AUTOSAR XML (schema 00053)
package /MICROSAR/NvM_swc/DataTypes
  impl type NvM_BlockIdType: range raw 1..32767, implementation-data-type=uint16
package /MICROSAR/NvM_swc/Interfaces
  client server interface NvMAdministration: is-service=true, service-kind=NON-VOLATILE-RAM-MANAGER
    operation SetBlockProtection: possible-error=NvMAdministration/E_NOT_OK
      arg ProtectionEnabled: type=boolean, direction=IN
    error E_NOT_OK: error-code=1
  client server interface NvMService_AC3_SRBS: is-service=true, service-kind=NON-VOLATILE-RAM-MANAGER
    7 x operation, all with possible-error=NvMService_AC3_SRBS/E_NOT_OK:
      GetErrorStatus
        arg ErrorStatus: type=NvM_RequestResultType, direction=OUT
      SetRamBlockStatus
        arg RamBlockStatus: type=boolean, direction=IN
      ReadBlock
        arg DstPtr: type=dtRef_VOID, direction=IN
      WriteBlock
        arg SrcPtr: type=dtRef_const_VOID, direction=IN
      RestoreBlockDefaults
        arg DstPtr: type=dtRef_VOID, direction=IN
      InvalidateNvBlock
      EraseBlock
    error E_NOT_OK: error-code=1
  client server interface NvMService_AC3_SRBS_Defs: is-service=true, service-kind=NON-VOLATILE-RAM-MANAGER
    7 x operation, all with possible-error=NvMService_AC3_SRBS_Defs/E_NOT_OK:
      GetErrorStatus
        arg ErrorStatus: type=NvM_RequestResultType, direction=OUT
      SetRamBlockStatus
        arg RamBlockStatus: type=boolean, direction=IN
      ReadBlock
        arg DstPtr: type=dtRef_VOID, direction=IN
      WriteBlock
        arg SrcPtr: type=dtRef_const_VOID, direction=IN
      RestoreBlockDefaults
        arg DstPtr: type=dtRef_VOID, direction=IN
      InvalidateNvBlock
      EraseBlock
    error E_NOT_OK: error-code=1
package /MICROSAR/NvM_swc/ComponentTypes
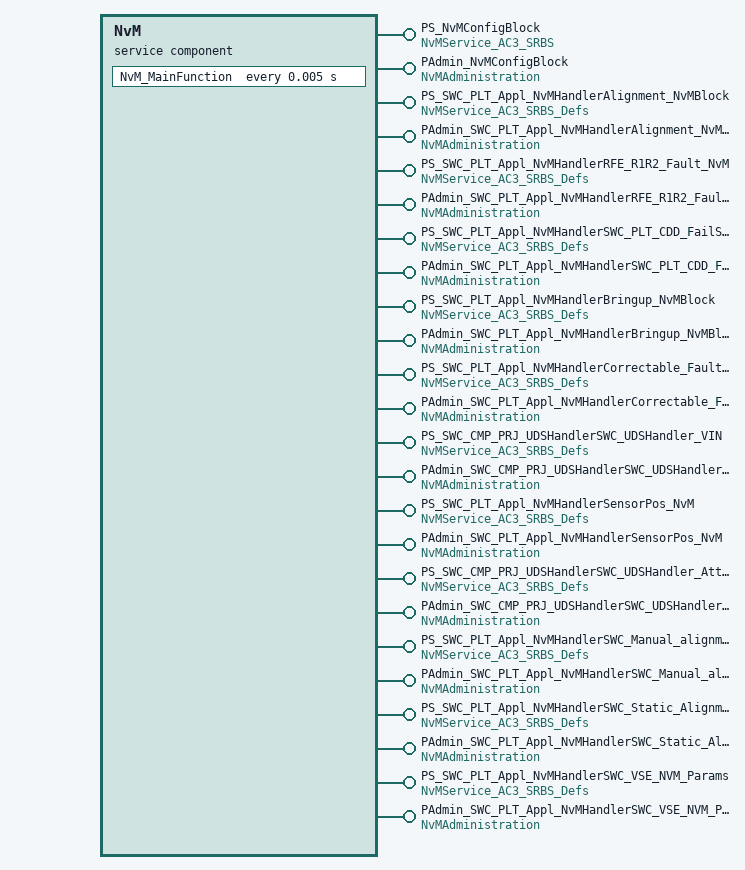
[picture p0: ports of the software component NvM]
  service sw component type NvM: category=SERVICE_COMPONENT
    24 x provide port:
      PS_NvMConfigBlock: provided-interface=NvMService_AC3_SRBS
      PAdmin_NvMConfigBlock: provided-interface=NvMAdministration
      PS_SWC_PLT_Appl_NvMHandlerAlignment_NvMBlock: provided-interface=NvMService_AC3_SRBS_Defs
      PAdmin_SWC_PLT_Appl_NvMHandlerAlignment_NvMBlock: provided-interface=NvMAdministration
      PS_SWC_PLT_Appl_NvMHandlerRFE_R1R2_Fault_NvM: provided-interface=NvMService_AC3_SRBS_Defs
      PAdmin_SWC_PLT_Appl_NvMHandlerRFE_R1R2_Fault_NvM: provided-interface=NvMAdministration
      PS_SWC_PLT_Appl_NvMHandlerSWC_PLT_CDD_FailSafe: provided-interface=NvMService_AC3_SRBS_Defs
      PAdmin_SWC_PLT_Appl_NvMHandlerSWC_PLT_CDD_FailSafe: provided-interface=NvMAdministration
      PS_SWC_PLT_Appl_NvMHandlerBringup_NvMBlock: provided-interface=NvMService_AC3_SRBS_Defs
      PAdmin_SWC_PLT_Appl_NvMHandlerBringup_NvMBlock: provided-interface=NvMAdministration
      PS_SWC_PLT_Appl_NvMHandlerCorrectable_Fault_NvM: provided-interface=NvMService_AC3_SRBS_Defs
      PAdmin_SWC_PLT_Appl_NvMHandlerCorrectable_Fault_NvM: provided-interface=NvMAdministration
      PS_SWC_CMP_PRJ_UDSHandlerSWC_UDSHandler_VIN: provided-interface=NvMService_AC3_SRBS_Defs
      PAdmin_SWC_CMP_PRJ_UDSHandlerSWC_UDSHandler_VIN: provided-interface=NvMAdministration
      PS_SWC_PLT_Appl_NvMHandlerSensorPos_NvM: provided-interface=NvMService_AC3_SRBS_Defs
      PAdmin_SWC_PLT_Appl_NvMHandlerSensorPos_NvM: provided-interface=NvMAdministration
      PS_SWC_CMP_PRJ_UDSHandlerSWC_UDSHandler_Attemptcounter: provided-interface=NvMService_AC3_SRBS_Defs
      PAdmin_SWC_CMP_PRJ_UDSHandlerSWC_UDSHandler_Attemptcounter: provided-interface=NvMAdministration
      PS_SWC_PLT_Appl_NvMHandlerSWC_Manual_alignment_Execution: provided-interface=NvMService_AC3_SRBS_Defs
      PAdmin_SWC_PLT_Appl_NvMHandlerSWC_Manual_alignment_Execution: provided-interface=NvMAdministration
      PS_SWC_PLT_Appl_NvMHandlerSWC_Static_Alignment_Write_Parameters: provided-interface=NvMService_AC3_SRBS_Defs
      PAdmin_SWC_PLT_Appl_NvMHandlerSWC_Static_Alignment_Write_Parameters: provided-interface=NvMAdministration
      PS_SWC_PLT_Appl_NvMHandlerSWC_VSE_NVM_Params: provided-interface=NvMService_AC3_SRBS_Defs
      PAdmin_SWC_PLT_Appl_NvMHandlerSWC_VSE_NVM_Params: provided-interface=NvMAdministration
    behavior NvMInternalBehavior: handle-termination-and-restart=NO-SUPPORT
      timing event Timer_NvM_MainFunction: start-on-event=NvM_MainFunction, period=0.005
      96 x operation invoked event:
        OpEventGetErrorStatus_GetErrorStatus_PS_NvMConfigBlock: start-on-event=GetErrorStatus, operation=PS_NvMConfigBlock.GetErrorStatus
        OpEventSetRamBlockStatus_SetRamBlockStatus_PS_NvMConfigBlock: start-on-event=SetRamBlockStatus, operation=PS_NvMConfigBlock.SetRamBlockStatus
        OpEventReadBlock_ReadBlock_PS_NvMConfigBlock: start-on-event=ReadBlock, operation=PS_NvMConfigBlock.ReadBlock
        OpEventWriteBlock_WriteBlock_PS_NvMConfigBlock: start-on-event=WriteBlock, operation=PS_NvMConfigBlock.WriteBlock
        OpEventRestoreBlockDefaults_RestoreBlockDefaults_PS_NvMConfigBlock: start-on-event=RestoreBlockDefaults, operation=PS_NvMConfigBlock.RestoreBlockDefaults
        OpEventInvalidateNvBlock_InvalidateNvBlock_PS_NvMConfigBlock: start-on-event=InvalidateNvBlock, operation=PS_NvMConfigBlock.InvalidateNvBlock
        OpEventEraseBlock_EraseBlock_PS_NvMConfigBlock: start-on-event=EraseBlock, operation=PS_NvMConfigBlock.EraseBlock
        OpEventSetBlockProtection_SetBlockProtection_PAdmin_NvMConfigBlock: start-on-event=SetBlockProtection, operation=PAdmin_NvMConfigBlock.SetBlockProtection
        OpEventGetErrorStatus_GetErrorStatus_PS_SWC_PLT_Appl_NvMHandlerAlignment_NvMBlock: start-on-event=GetErrorStatus, operation=PS_SWC_PLT_Appl_NvMHandlerAlignment_NvMBlock.GetErrorStatus
        OpEventGetErrorStatus_GetErrorStatus_PS_SWC_PLT_Appl_NvMHandlerRFE_R1R2_Fault_NvM: start-on-event=GetErrorStatus, operation=PS_SWC_PLT_Appl_NvMHandlerRFE_R1R2_Fault_NvM.GetErrorStatus
        OpEventGetErrorStatus_GetErrorStatus_PS_SWC_PLT_Appl_NvMHandlerSWC_PLT_CDD_FailSafe: start-on-event=GetErrorStatus, operation=PS_SWC_PLT_Appl_NvMHandlerSWC_PLT_CDD_FailSafe.GetErrorStatus
        OpEventSetRamBlockStatus_SetRamBlockStatus_PS_SWC_PLT_Appl_NvMHandlerAlignment_NvMBlock: start-on-event=SetRamBlockStatus, operation=PS_SWC_PLT_Appl_NvMHandlerAlignment_NvMBlock.SetRamBlockStatus
        OpEventSetRamBlockStatus_SetRamBlockStatus_PS_SWC_PLT_Appl_NvMHandlerRFE_R1R2_Fault_NvM: start-on-event=SetRamBlockStatus, operation=PS_SWC_PLT_Appl_NvMHandlerRFE_R1R2_Fault_NvM.SetRamBlockStatus
        OpEventSetRamBlockStatus_SetRamBlockStatus_PS_SWC_PLT_Appl_NvMHandlerSWC_PLT_CDD_FailSafe: start-on-event=SetRamBlockStatus, operation=PS_SWC_PLT_Appl_NvMHandlerSWC_PLT_CDD_FailSafe.SetRamBlockStatus
        OpEventReadBlock_ReadBlock_PS_SWC_PLT_Appl_NvMHandlerAlignment_NvMBlock: start-on-event=ReadBlock, operation=PS_SWC_PLT_Appl_NvMHandlerAlignment_NvMBlock.ReadBlock
        OpEventReadBlock_ReadBlock_PS_SWC_PLT_Appl_NvMHandlerRFE_R1R2_Fault_NvM: start-on-event=ReadBlock, operation=PS_SWC_PLT_Appl_NvMHandlerRFE_R1R2_Fault_NvM.ReadBlock
        OpEventReadBlock_ReadBlock_PS_SWC_PLT_Appl_NvMHandlerSWC_PLT_CDD_FailSafe: start-on-event=ReadBlock, operation=PS_SWC_PLT_Appl_NvMHandlerSWC_PLT_CDD_FailSafe.ReadBlock
        OpEventWriteBlock_WriteBlock_PS_SWC_PLT_Appl_NvMHandlerAlignment_NvMBlock: start-on-event=WriteBlock, operation=PS_SWC_PLT_Appl_NvMHandlerAlignment_NvMBlock.WriteBlock
        OpEventWriteBlock_WriteBlock_PS_SWC_PLT_Appl_NvMHandlerRFE_R1R2_Fault_NvM: start-on-event=WriteBlock, operation=PS_SWC_PLT_Appl_NvMHandlerRFE_R1R2_Fault_NvM.WriteBlock
        OpEventWriteBlock_WriteBlock_PS_SWC_PLT_Appl_NvMHandlerSWC_PLT_CDD_FailSafe: start-on-event=WriteBlock, operation=PS_SWC_PLT_Appl_NvMHandlerSWC_PLT_CDD_FailSafe.WriteBlock
        OpEventRestoreBlockDefaults_RestoreBlockDefaults_PS_SWC_PLT_Appl_NvMHandlerAlignment_NvMBlock: start-on-event=RestoreBlockDefaults, operation=PS_SWC_PLT_Appl_NvMHandlerAlignment_NvMBlock.RestoreBlockDefaults
        OpEventRestoreBlockDefaults_RestoreBlockDefaults_PS_SWC_PLT_Appl_NvMHandlerRFE_R1R2_Fault_NvM: start-on-event=RestoreBlockDefaults, operation=PS_SWC_PLT_Appl_NvMHandlerRFE_R1R2_Fault_NvM.RestoreBlockDefaults
        OpEventRestoreBlockDefaults_RestoreBlockDefaults_PS_SWC_PLT_Appl_NvMHandlerSWC_PLT_CDD_FailSafe: start-on-event=RestoreBlockDefaults, operation=PS_SWC_PLT_Appl_NvMHandlerSWC_PLT_CDD_FailSafe.RestoreBlockDefaults
        OpEventInvalidateNvBlock_InvalidateNvBlock_PS_SWC_PLT_Appl_NvMHandlerAlignment_NvMBlock: start-on-event=InvalidateNvBlock, operation=PS_SWC_PLT_Appl_NvMHandlerAlignment_NvMBlock.InvalidateNvBlock
        OpEventInvalidateNvBlock_InvalidateNvBlock_PS_SWC_PLT_Appl_NvMHandlerRFE_R1R2_Fault_NvM: start-on-event=InvalidateNvBlock, operation=PS_SWC_PLT_Appl_NvMHandlerRFE_R1R2_Fault_NvM.InvalidateNvBlock
        OpEventInvalidateNvBlock_InvalidateNvBlock_PS_SWC_PLT_Appl_NvMHandlerSWC_PLT_CDD_FailSafe: start-on-event=InvalidateNvBlock, operation=PS_SWC_PLT_Appl_NvMHandlerSWC_PLT_CDD_FailSafe.InvalidateNvBlock
        OpEventEraseBlock_EraseBlock_PS_SWC_PLT_Appl_NvMHandlerAlignment_NvMBlock: start-on-event=EraseBlock, operation=PS_SWC_PLT_Appl_NvMHandlerAlignment_NvMBlock.EraseBlock
        OpEventEraseBlock_EraseBlock_PS_SWC_PLT_Appl_NvMHandlerRFE_R1R2_Fault_NvM: start-on-event=EraseBlock, operation=PS_SWC_PLT_Appl_NvMHandlerRFE_R1R2_Fault_NvM.EraseBlock
        OpEventEraseBlock_EraseBlock_PS_SWC_PLT_Appl_NvMHandlerSWC_PLT_CDD_FailSafe: start-on-event=EraseBlock, operation=PS_SWC_PLT_Appl_NvMHandlerSWC_PLT_CDD_FailSafe.EraseBlock
        OpEventSetBlockProtection_SetBlockProtection_PAdmin_SWC_PLT_Appl_NvMHandlerAlignment_NvMBlock: start-on-event=SetBlockProtection, operation=PAdmin_SWC_PLT_Appl_NvMHandlerAlignment_NvMBlock.SetBlockProtection
        OpEventSetBlockProtection_SetBlockProtection_PAdmin_SWC_PLT_Appl_NvMHandlerRFE_R1R2_Fault_NvM: start-on-event=SetBlockProtection, operation=PAdmin_SWC_PLT_Appl_NvMHandlerRFE_R1R2_Fault_NvM.SetBlockProtection
        OpEventSetBlockProtection_SetBlockProtection_PAdmin_SWC_PLT_Appl_NvMHandlerSWC_PLT_CDD_FailSafe: start-on-event=SetBlockProtection, operation=PAdmin_SWC_PLT_Appl_NvMHandlerSWC_PLT_CDD_FailSafe.SetBlockProtection
        OpEventGetErrorStatus_GetErrorStatus_PS_SWC_PLT_Appl_NvMHandlerBringup_NvMBlock: start-on-event=GetErrorStatus, operation=PS_SWC_PLT_Appl_NvMHandlerBringup_NvMBlock.GetErrorStatus
        OpEventSetRamBlockStatus_SetRamBlockStatus_PS_SWC_PLT_Appl_NvMHandlerBringup_NvMBlock: start-on-event=SetRamBlockStatus, operation=PS_SWC_PLT_Appl_NvMHandlerBringup_NvMBlock.SetRamBlockStatus
        OpEventReadBlock_ReadBlock_PS_SWC_PLT_Appl_NvMHandlerBringup_NvMBlock: start-on-event=ReadBlock, operation=PS_SWC_PLT_Appl_NvMHandlerBringup_NvMBlock.ReadBlock
        OpEventWriteBlock_WriteBlock_PS_SWC_PLT_Appl_NvMHandlerBringup_NvMBlock: start-on-event=WriteBlock, operation=PS_SWC_PLT_Appl_NvMHandlerBringup_NvMBlock.WriteBlock
        OpEventRestoreBlockDefaults_RestoreBlockDefaults_PS_SWC_PLT_Appl_NvMHandlerBringup_NvMBlock: start-on-event=RestoreBlockDefaults, operation=PS_SWC_PLT_Appl_NvMHandlerBringup_NvMBlock.RestoreBlockDefaults
        OpEventInvalidateNvBlock_InvalidateNvBlock_PS_SWC_PLT_Appl_NvMHandlerBringup_NvMBlock: start-on-event=InvalidateNvBlock, operation=PS_SWC_PLT_Appl_NvMHandlerBringup_NvMBlock.InvalidateNvBlock
        OpEventEraseBlock_EraseBlock_PS_SWC_PLT_Appl_NvMHandlerBringup_NvMBlock: start-on-event=EraseBlock, operation=PS_SWC_PLT_Appl_NvMHandlerBringup_NvMBlock.EraseBlock
        OpEventSetBlockProtection_SetBlockProtection_PAdmin_SWC_PLT_Appl_NvMHandlerBringup_NvMBlock: start-on-event=SetBlockProtection, operation=PAdmin_SWC_PLT_Appl_NvMHandlerBringup_NvMBlock.SetBlockProtection
        OpEventGetErrorStatus_GetErrorStatus_PS_SWC_PLT_Appl_NvMHandlerCorrectable_Fault_NvM: start-on-event=GetErrorStatus, operation=PS_SWC_PLT_Appl_NvMHandlerCorrectable_Fault_NvM.GetErrorStatus
        OpEventSetRamBlockStatus_SetRamBlockStatus_PS_SWC_PLT_Appl_NvMHandlerCorrectable_Fault_NvM: start-on-event=SetRamBlockStatus, operation=PS_SWC_PLT_Appl_NvMHandlerCorrectable_Fault_NvM.SetRamBlockStatus
        OpEventReadBlock_ReadBlock_PS_SWC_PLT_Appl_NvMHandlerCorrectable_Fault_NvM: start-on-event=ReadBlock, operation=PS_SWC_PLT_Appl_NvMHandlerCorrectable_Fault_NvM.ReadBlock
        OpEventWriteBlock_WriteBlock_PS_SWC_PLT_Appl_NvMHandlerCorrectable_Fault_NvM: start-on-event=WriteBlock, operation=PS_SWC_PLT_Appl_NvMHandlerCorrectable_Fault_NvM.WriteBlock
        OpEventRestoreBlockDefaults_RestoreBlockDefaults_PS_SWC_PLT_Appl_NvMHandlerCorrectable_Fault_NvM: start-on-event=RestoreBlockDefaults, operation=PS_SWC_PLT_Appl_NvMHandlerCorrectable_Fault_NvM.RestoreBlockDefaults
        OpEventInvalidateNvBlock_InvalidateNvBlock_PS_SWC_PLT_Appl_NvMHandlerCorrectable_Fault_NvM: start-on-event=InvalidateNvBlock, operation=PS_SWC_PLT_Appl_NvMHandlerCorrectable_Fault_NvM.InvalidateNvBlock
        OpEventEraseBlock_EraseBlock_PS_SWC_PLT_Appl_NvMHandlerCorrectable_Fault_NvM: start-on-event=EraseBlock, operation=PS_SWC_PLT_Appl_NvMHandlerCorrectable_Fault_NvM.EraseBlock
        OpEventSetBlockProtection_SetBlockProtection_PAdmin_SWC_PLT_Appl_NvMHandlerCorrectable_Fault_NvM: start-on-event=SetBlockProtection, operation=PAdmin_SWC_PLT_Appl_NvMHandlerCorrectable_Fault_NvM.SetBlockProtection
        OpEventGetErrorStatus_GetErrorStatus_PS_SWC_CMP_PRJ_UDSHandlerSWC_UDSHandler_VIN: start-on-event=GetErrorStatus, operation=PS_SWC_CMP_PRJ_UDSHandlerSWC_UDSHandler_VIN.GetErrorStatus
        OpEventSetRamBlockStatus_SetRamBlockStatus_PS_SWC_CMP_PRJ_UDSHandlerSWC_UDSHandler_VIN: start-on-event=SetRamBlockStatus, operation=PS_SWC_CMP_PRJ_UDSHandlerSWC_UDSHandler_VIN.SetRamBlockStatus
        OpEventReadBlock_ReadBlock_PS_SWC_CMP_PRJ_UDSHandlerSWC_UDSHandler_VIN: start-on-event=ReadBlock, operation=PS_SWC_CMP_PRJ_UDSHandlerSWC_UDSHandler_VIN.ReadBlock
        OpEventWriteBlock_WriteBlock_PS_SWC_CMP_PRJ_UDSHandlerSWC_UDSHandler_VIN: start-on-event=WriteBlock, operation=PS_SWC_CMP_PRJ_UDSHandlerSWC_UDSHandler_VIN.WriteBlock
        OpEventRestoreBlockDefaults_RestoreBlockDefaults_PS_SWC_CMP_PRJ_UDSHandlerSWC_UDSHandler_VIN: start-on-event=RestoreBlockDefaults, operation=PS_SWC_CMP_PRJ_UDSHandlerSWC_UDSHandler_VIN.RestoreBlockDefaults
        OpEventInvalidateNvBlock_InvalidateNvBlock_PS_SWC_CMP_PRJ_UDSHandlerSWC_UDSHandler_VIN: start-on-event=InvalidateNvBlock, operation=PS_SWC_CMP_PRJ_UDSHandlerSWC_UDSHandler_VIN.InvalidateNvBlock
        OpEventEraseBlock_EraseBlock_PS_SWC_CMP_PRJ_UDSHandlerSWC_UDSHandler_VIN: start-on-event=EraseBlock, operation=PS_SWC_CMP_PRJ_UDSHandlerSWC_UDSHandler_VIN.EraseBlock
        OpEventSetBlockProtection_SetBlockProtection_PAdmin_SWC_CMP_PRJ_UDSHandlerSWC_UDSHandler_VIN: start-on-event=SetBlockProtection, operation=PAdmin_SWC_CMP_PRJ_UDSHandlerSWC_UDSHandler_VIN.SetBlockProtection
        OpEventGetErrorStatus_GetErrorStatus_PS_SWC_PLT_Appl_NvMHandlerSensorPos_NvM: start-on-event=GetErrorStatus, operation=PS_SWC_PLT_Appl_NvMHandlerSensorPos_NvM.GetErrorStatus
        OpEventSetRamBlockStatus_SetRamBlockStatus_PS_SWC_PLT_Appl_NvMHandlerSensorPos_NvM: start-on-event=SetRamBlockStatus, operation=PS_SWC_PLT_Appl_NvMHandlerSensorPos_NvM.SetRamBlockStatus
        OpEventReadBlock_ReadBlock_PS_SWC_PLT_Appl_NvMHandlerSensorPos_NvM: start-on-event=ReadBlock, operation=PS_SWC_PLT_Appl_NvMHandlerSensorPos_NvM.ReadBlock
        OpEventWriteBlock_WriteBlock_PS_SWC_PLT_Appl_NvMHandlerSensorPos_NvM: start-on-event=WriteBlock, operation=PS_SWC_PLT_Appl_NvMHandlerSensorPos_NvM.WriteBlock
        OpEventRestoreBlockDefaults_RestoreBlockDefaults_PS_SWC_PLT_Appl_NvMHandlerSensorPos_NvM: start-on-event=RestoreBlockDefaults, operation=PS_SWC_PLT_Appl_NvMHandlerSensorPos_NvM.RestoreBlockDefaults
        OpEventInvalidateNvBlock_InvalidateNvBlock_PS_SWC_PLT_Appl_NvMHandlerSensorPos_NvM: start-on-event=InvalidateNvBlock, operation=PS_SWC_PLT_Appl_NvMHandlerSensorPos_NvM.InvalidateNvBlock
        OpEventEraseBlock_EraseBlock_PS_SWC_PLT_Appl_NvMHandlerSensorPos_NvM: start-on-event=EraseBlock, operation=PS_SWC_PLT_Appl_NvMHandlerSensorPos_NvM.EraseBlock
        OpEventSetBlockProtection_SetBlockProtection_PAdmin_SWC_PLT_Appl_NvMHandlerSensorPos_NvM: start-on-event=SetBlockProtection, operation=PAdmin_SWC_PLT_Appl_NvMHandlerSensorPos_NvM.SetBlockProtection
        OpEventGetErrorStatus_GetErrorStatus_PS_SWC_CMP_PRJ_UDSHandlerSWC_UDSHandler_Attemptcounter: start-on-event=GetErrorStatus, operation=PS_SWC_CMP_PRJ_UDSHandlerSWC_UDSHandler_Attemptcounter.GetErrorStatus
        OpEventSetRamBlockStatus_SetRamBlockStatus_PS_SWC_CMP_PRJ_UDSHandlerSWC_UDSHandler_Attemptcounter: start-on-event=SetRamBlockStatus, operation=PS_SWC_CMP_PRJ_UDSHandlerSWC_UDSHandler_Attemptcounter.SetRamBlockStatus
        OpEventReadBlock_ReadBlock_PS_SWC_CMP_PRJ_UDSHandlerSWC_UDSHandler_Attemptcounter: start-on-event=ReadBlock, operation=PS_SWC_CMP_PRJ_UDSHandlerSWC_UDSHandler_Attemptcounter.ReadBlock
        OpEventWriteBlock_WriteBlock_PS_SWC_CMP_PRJ_UDSHandlerSWC_UDSHandler_Attemptcounter: start-on-event=WriteBlock, operation=PS_SWC_CMP_PRJ_UDSHandlerSWC_UDSHandler_Attemptcounter.WriteBlock
        OpEventRestoreBlockDefaults_RestoreBlockDefaults_PS_SWC_CMP_PRJ_UDSHandlerSWC_UDSHandler_Attemptcounter: start-on-event=RestoreBlockDefaults, operation=PS_SWC_CMP_PRJ_UDSHandlerSWC_UDSHandler_Attemptcounter.RestoreBlockDefaults
        OpEventInvalidateNvBlock_InvalidateNvBlock_PS_SWC_CMP_PRJ_UDSHandlerSWC_UDSHandler_Attemptcounter: start-on-event=InvalidateNvBlock, operation=PS_SWC_CMP_PRJ_UDSHandlerSWC_UDSHandler_Attemptcounter.InvalidateNvBlock
        OpEventEraseBlock_EraseBlock_PS_SWC_CMP_PRJ_UDSHandlerSWC_UDSHandler_Attemptcounter: start-on-event=EraseBlock, operation=PS_SWC_CMP_PRJ_UDSHandlerSWC_UDSHandler_Attemptcounter.EraseBlock
        OpEventSetBlockProtection_SetBlockProtection_PAdmin_SWC_CMP_PRJ_UDSHandlerSWC_UDSHandler_Attemptcounter: start-on-event=SetBlockProtection, operation=PAdmin_SWC_CMP_PRJ_UDSHandlerSWC_UDSHandler_Attemptcounter.SetBlockProtection
        OpEventGetErrorStatus_GetErrorStatus_PS_SWC_PLT_Appl_NvMHandlerSWC_Manual_alignment_Execution: start-on-event=GetErrorStatus, operation=PS_SWC_PLT_Appl_NvMHandlerSWC_Manual_alignment_Execution.GetErrorStatus
        OpEventSetRamBlockStatus_SetRamBlockStatus_PS_SWC_PLT_Appl_NvMHandlerSWC_Manual_alignment_Execution: start-on-event=SetRamBlockStatus, operation=PS_SWC_PLT_Appl_NvMHandlerSWC_Manual_alignment_Execution.SetRamBlockStatus
        OpEventReadBlock_ReadBlock_PS_SWC_PLT_Appl_NvMHandlerSWC_Manual_alignment_Execution: start-on-event=ReadBlock, operation=PS_SWC_PLT_Appl_NvMHandlerSWC_Manual_alignment_Execution.ReadBlock
        OpEventWriteBlock_WriteBlock_PS_SWC_PLT_Appl_NvMHandlerSWC_Manual_alignment_Execution: start-on-event=WriteBlock, operation=PS_SWC_PLT_Appl_NvMHandlerSWC_Manual_alignment_Execution.WriteBlock
        OpEventRestoreBlockDefaults_RestoreBlockDefaults_PS_SWC_PLT_Appl_NvMHandlerSWC_Manual_alignment_Execution: start-on-event=RestoreBlockDefaults, operation=PS_SWC_PLT_Appl_NvMHandlerSWC_Manual_alignment_Execution.RestoreBlockDefaults
        OpEventInvalidateNvBlock_InvalidateNvBlock_PS_SWC_PLT_Appl_NvMHandlerSWC_Manual_alignment_Execution: start-on-event=InvalidateNvBlock, operation=PS_SWC_PLT_Appl_NvMHandlerSWC_Manual_alignment_Execution.InvalidateNvBlock
        OpEventEraseBlock_EraseBlock_PS_SWC_PLT_Appl_NvMHandlerSWC_Manual_alignment_Execution: start-on-event=EraseBlock, operation=PS_SWC_PLT_Appl_NvMHandlerSWC_Manual_alignment_Execution.EraseBlock
        OpEventSetBlockProtection_SetBlockProtection_PAdmin_SWC_PLT_Appl_NvMHandlerSWC_Manual_alignment_Execution: start-on-event=SetBlockProtection, operation=PAdmin_SWC_PLT_Appl_NvMHandlerSWC_Manual_alignment_Execution.SetBlockProtection
        OpEventGetErrorStatus_GetErrorStatus_PS_SWC_PLT_Appl_NvMHandlerSWC_Static_Alignment_Write_Parameters: start-on-event=GetErrorStatus, operation=PS_SWC_PLT_Appl_NvMHandlerSWC_Static_Alignment_Write_Parameters.GetErrorStatus
        OpEventGetErrorStatus_GetErrorStatus_PS_SWC_PLT_Appl_NvMHandlerSWC_VSE_NVM_Params: start-on-event=GetErrorStatus, operation=PS_SWC_PLT_Appl_NvMHandlerSWC_VSE_NVM_Params.GetErrorStatus
        OpEventSetRamBlockStatus_SetRamBlockStatus_PS_SWC_PLT_Appl_NvMHandlerSWC_Static_Alignment_Write_Parameters: start-on-event=SetRamBlockStatus, operation=PS_SWC_PLT_Appl_NvMHandlerSWC_Static_Alignment_Write_Parameters.SetRamBlockStatus
        OpEventSetRamBlockStatus_SetRamBlockStatus_PS_SWC_PLT_Appl_NvMHandlerSWC_VSE_NVM_Params: start-on-event=SetRamBlockStatus, operation=PS_SWC_PLT_Appl_NvMHandlerSWC_VSE_NVM_Params.SetRamBlockStatus
        OpEventReadBlock_ReadBlock_PS_SWC_PLT_Appl_NvMHandlerSWC_Static_Alignment_Write_Parameters: start-on-event=ReadBlock, operation=PS_SWC_PLT_Appl_NvMHandlerSWC_Static_Alignment_Write_Parameters.ReadBlock
        OpEventReadBlock_ReadBlock_PS_SWC_PLT_Appl_NvMHandlerSWC_VSE_NVM_Params: start-on-event=ReadBlock, operation=PS_SWC_PLT_Appl_NvMHandlerSWC_VSE_NVM_Params.ReadBlock
        OpEventWriteBlock_WriteBlock_PS_SWC_PLT_Appl_NvMHandlerSWC_Static_Alignment_Write_Parameters: start-on-event=WriteBlock, operation=PS_SWC_PLT_Appl_NvMHandlerSWC_Static_Alignment_Write_Parameters.WriteBlock
        OpEventWriteBlock_WriteBlock_PS_SWC_PLT_Appl_NvMHandlerSWC_VSE_NVM_Params: start-on-event=WriteBlock, operation=PS_SWC_PLT_Appl_NvMHandlerSWC_VSE_NVM_Params.WriteBlock
        OpEventRestoreBlockDefaults_RestoreBlockDefaults_PS_SWC_PLT_Appl_NvMHandlerSWC_Static_Alignment_Write_Parameters: start-on-event=RestoreBlockDefaults, operation=PS_SWC_PLT_Appl_NvMHandlerSWC_Static_Alignment_Write_Parameters.RestoreBlockDefaults
        OpEventRestoreBlockDefaults_RestoreBlockDefaults_PS_SWC_PLT_Appl_NvMHandlerSWC_VSE_NVM_Params: start-on-event=RestoreBlockDefaults, operation=PS_SWC_PLT_Appl_NvMHandlerSWC_VSE_NVM_Params.RestoreBlockDefaults
        OpEventInvalidateNvBlock_InvalidateNvBlock_PS_SWC_PLT_Appl_NvMHandlerSWC_Static_Alignment_Write_Parameters: start-on-event=InvalidateNvBlock, operation=PS_SWC_PLT_Appl_NvMHandlerSWC_Static_Alignment_Write_Parameters.InvalidateNvBlock
        OpEventInvalidateNvBlock_InvalidateNvBlock_PS_SWC_PLT_Appl_NvMHandlerSWC_VSE_NVM_Params: start-on-event=InvalidateNvBlock, operation=PS_SWC_PLT_Appl_NvMHandlerSWC_VSE_NVM_Params.InvalidateNvBlock
        OpEventEraseBlock_EraseBlock_PS_SWC_PLT_Appl_NvMHandlerSWC_Static_Alignment_Write_Parameters: start-on-event=EraseBlock, operation=PS_SWC_PLT_Appl_NvMHandlerSWC_Static_Alignment_Write_Parameters.EraseBlock
        OpEventEraseBlock_EraseBlock_PS_SWC_PLT_Appl_NvMHandlerSWC_VSE_NVM_Params: start-on-event=EraseBlock, operation=PS_SWC_PLT_Appl_NvMHandlerSWC_VSE_NVM_Params.EraseBlock
        OpEventSetBlockProtection_SetBlockProtection_PAdmin_SWC_PLT_Appl_NvMHandlerSWC_Static_Alignment_Write_Parameters: start-on-event=SetBlockProtection, operation=PAdmin_SWC_PLT_Appl_NvMHandlerSWC_Static_Alignment_Write_Parameters.SetBlockProtection
        OpEventSetBlockProtection_SetBlockProtection_PAdmin_SWC_PLT_Appl_NvMHandlerSWC_VSE_NVM_Params: start-on-event=SetBlockProtection, operation=PAdmin_SWC_PLT_Appl_NvMHandlerSWC_VSE_NVM_Params.SetBlockProtection
      port-api-options:
        {enable-take-address=true, indirect-api=false, port-defined-argument-value{value=1, value-type=NvM_BlockIdType}, port=PS_NvMConfigBlock}
        {enable-take-address=true, indirect-api=false, port-defined-argument-value{value=1, value-type=NvM_BlockIdType}, port=PAdmin_NvMConfigBlock}
        {enable-take-address=true, indirect-api=false, port-defined-argument-value{value=2, value-type=NvM_BlockIdType}, port=PS_SWC_PLT_Appl_NvMHandlerAlignment_NvMBlock}
        {enable-take-address=true, indirect-api=false, port-defined-argument-value{value=2, value-type=NvM_BlockIdType}, port=PAdmin_SWC_PLT_Appl_NvMHandlerAlignment_NvMBlock}
        {enable-take-address=true, indirect-api=false, port-defined-argument-value{value=4, value-type=NvM_BlockIdType}, port=PS_SWC_PLT_Appl_NvMHandlerRFE_R1R2_Fault_NvM}
        {enable-take-address=true, indirect-api=false, port-defined-argument-value{value=4, value-type=NvM_BlockIdType}, port=PAdmin_SWC_PLT_Appl_NvMHandlerRFE_R1R2_Fault_NvM}
        {enable-take-address=true, indirect-api=false, port-defined-argument-value{value=5, value-type=NvM_BlockIdType}, port=PS_SWC_PLT_Appl_NvMHandlerSWC_PLT_CDD_FailSafe}
        {enable-take-address=true, indirect-api=false, port-defined-argument-value{value=5, value-type=NvM_BlockIdType}, port=PAdmin_SWC_PLT_Appl_NvMHandlerSWC_PLT_CDD_FailSafe}
        {enable-take-address=true, indirect-api=false, port-defined-argument-value{value=3, value-type=NvM_BlockIdType}, port=PS_SWC_PLT_Appl_NvMHandlerBringup_NvMBlock}
        {enable-take-address=true, indirect-api=false, port-defined-argument-value{value=3, value-type=NvM_BlockIdType}, port=PAdmin_SWC_PLT_Appl_NvMHandlerBringup_NvMBlock}
        {enable-take-address=true, indirect-api=false, port-defined-argument-value{value=7, value-type=NvM_BlockIdType}, port=PS_SWC_PLT_Appl_NvMHandlerCorrectable_Fault_NvM}
        {enable-take-address=true, indirect-api=false, port-defined-argument-value{value=7, value-type=NvM_BlockIdType}, port=PAdmin_SWC_PLT_Appl_NvMHandlerCorrectable_Fault_NvM}
        {enable-take-address=true, indirect-api=false, port-defined-argument-value{value=20, value-type=NvM_BlockIdType}, port=PS_SWC_CMP_PRJ_UDSHandlerSWC_UDSHandler_VIN}
        {enable-take-address=true, indirect-api=false, port-defined-argument-value{value=20, value-type=NvM_BlockIdType}, port=PAdmin_SWC_CMP_PRJ_UDSHandlerSWC_UDSHandler_VIN}
        {enable-take-address=true, indirect-api=false, port-defined-argument-value{value=21, value-type=NvM_BlockIdType}, port=PS_SWC_PLT_Appl_NvMHandlerSensorPos_NvM}
        {enable-take-address=true, indirect-api=false, port-defined-argument-value{value=21, value-type=NvM_BlockIdType}, port=PAdmin_SWC_PLT_Appl_NvMHandlerSensorPos_NvM}
        {enable-take-address=true, indirect-api=false, port-defined-argument-value{value=22, value-type=NvM_BlockIdType}, port=PAdmin_SWC_CMP_PRJ_UDSHandlerSWC_UDSHandler_Attemptcounter}
        {enable-take-address=true, indirect-api=false, port-defined-argument-value{value=23, value-type=NvM_BlockIdType}, port=PS_SWC_PLT_Appl_NvMHandlerSWC_Manual_alignment_Execution}
        {enable-take-address=true, indirect-api=false, port-defined-argument-value{value=23, value-type=NvM_BlockIdType}, port=PAdmin_SWC_PLT_Appl_NvMHandlerSWC_Manual_alignment_Execution}
        {enable-take-address=true, indirect-api=false, port-defined-argument-value{value=22, value-type=NvM_BlockIdType}, port=PS_SWC_CMP_PRJ_UDSHandlerSWC_UDSHandler_Attemptcounter}
        {enable-take-address=true, indirect-api=false, port-defined-argument-value{value=24, value-type=NvM_BlockIdType}, port=PS_SWC_PLT_Appl_NvMHandlerSWC_Static_Alignment_Write_Parameters}
        {enable-take-address=true, indirect-api=false, port-defined-argument-value{value=24, value-type=NvM_BlockIdType}, port=PAdmin_SWC_PLT_Appl_NvMHandlerSWC_Static_Alignment_Write_Parameters}
        {enable-take-address=true, indirect-api=false, port-defined-argument-value{value=25, value-type=NvM_BlockIdType}, port=PS_SWC_PLT_Appl_NvMHandlerSWC_VSE_NVM_Params}
        {enable-take-address=true, indirect-api=false, port-defined-argument-value{value=25, value-type=NvM_BlockIdType}, port=PAdmin_SWC_PLT_Appl_NvMHandlerSWC_VSE_NVM_Params}
      9 x runnable:
        NvM_MainFunction
        GetErrorStatus: can-be-invoked-concurrently=true, symbol=NvM_GetErrorStatus
        SetRamBlockStatus: can-be-invoked-concurrently=true, symbol=NvM_SetRamBlockStatus
        ReadBlock: can-be-invoked-concurrently=true, symbol=NvM_ReadBlock
        WriteBlock: can-be-invoked-concurrently=true, symbol=NvM_WriteBlock
        RestoreBlockDefaults: can-be-invoked-concurrently=true, symbol=NvM_RestoreBlockDefaults
        InvalidateNvBlock: can-be-invoked-concurrently=true, symbol=NvM_InvalidateNvBlock
        EraseBlock: can-be-invoked-concurrently=true, symbol=NvM_EraseNvBlock
        SetBlockProtection: can-be-invoked-concurrently=true, symbol=NvM_SetBlockProtection
  swc implementation NvMImplementation: programming-language=C, behavior=NvMInternalBehavior
